# EFM32PG23B310F128IM48 register map
Vendor: Silicon Labs; Series: EFM32; File version: B
Registers are 32-bit, read-write, reset 0x0 unless marked. A register's access mark holds for its fields unless they carry their own. Offsets are from the block's base; [hi:lo] are bit positions; lines under a group give offsets from that group; {n}, {i} and the like mark numbered series; 'fields as' and 'values as' point back to an identical list.

## IADC0_S — IADC0_S Registers
Base 0x49004000
Same registers: IADC0_NS 0x59004000
0x00 IPVERSION ro reset 0x2
  [31:0] IPVERSION — IP version ID
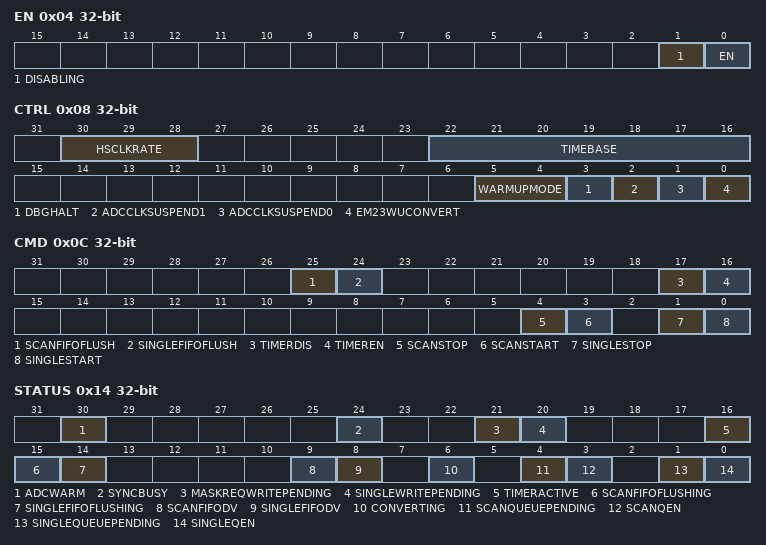
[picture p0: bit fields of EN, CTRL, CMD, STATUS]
0x04 EN — Enable
  [1] DISABLING ro — Disablement busy status
  [0] EN — Enable IADC Module
    0=DISABLE; 1=ENABLE
0x08 CTRL — Control
  [30:28] HSCLKRATE — High Speed Clock Rate
    0=DIV1 (Use CMU_CLK_ADC directly. The source clock must be 40 MHz or less.); 1=DIV2 (Divide CMU_CLK_ADC by 2 before using it. The resulting CLK_SRC_ADC must be 40 MHz or less.); 2=DIV3 (Divide CMU_CLK_ADC by 3 before using it. The resulting CLK_SRC_ADC must be 40 MHz or less.); 3=DIV4 (Divide CMU_CLK_ADC by 4 before using it. The resulting CLK_SRC_ADC must be 40 MHz or less.)
  [22:16] TIMEBASE
  [5:4] WARMUPMODE
    0=NORMAL (Shut down the IADC after conversions have completed.); 1=KEEPINSTANDBY (Switch to standby mode after conversions have completed. The next warmup time will require 1us.); 2=KEEPWARM (Keep IADC fully powered after conversions have completed.)
  [3] DBGHALT — Debug Halt
    0=NORMAL (Continue operation as normal during debug mode); 1=HALT (Complete the current conversion and then halt during debug mode)
  [2] ADCCLKSUSPEND1 — ADC_CLK Suspend - PRS1
    0=PRSWUDIS (Normal mode which does not disable the ADC_CLK.); 1=PRSWUEN (ADCCLKWUEN will gate off ADC_CLK until the trigger is detected provided the internal timer is not selected as the trigger. Once the trigger is detected the ADC_CLK will be started, the band gap will be started, the ADC will be warmed up, and the SCAN Table and the Single entry will be converted. Once the conversions are done, the ADC_CLK will be gated off.)
  [1] ADCCLKSUSPEND0 — ADC_CLK Suspend - PRS0
    values as ADCCLKSUSPEND1
  [0] EM23WUCONVERT — EM23 Wakeup on Conversion
    0=WUDVL (When using suspend mode, conversions performed in EM2 or EM3 should not wake up the DMA until the FIFO's DVL setting is reached. This saves more power for large OSR settings or infrequent sampling.); 1=WUCONVERT (When using suspend mode, conversions performed in EM2 or EM3 will wake up the DMA and keep it awake until the conversions are done, regardless of the DVL setting. This mode burns more power, but it is useful when the conversion rate is faster than the time for the DMA to cycle through wake up and going back to sleep as it converts more than 4 scan table entries. Without using the wake up on conversion mode, the FIFO may overflow while the DMA is going in and out of sleep.)
0x0C CMD wo — Command
  [25] SCANFIFOFLUSH — Flush the Scan FIFO
  [24] SINGLEFIFOFLUSH — Flush the Single FIFO
  [17] TIMERDIS — Timer Disable
  [16] TIMEREN — Timer Enable
  [4] SCANSTOP — Scan Queue Stop
  [3] SCANSTART — Scan Queue Start
  [1] SINGLESTOP — Single Queue Stop
  [0] SINGLESTART — Single Queue Start
0x10 TIMER
  [15:0] TIMER — Timer Period
0x14 STATUS ro
  [30] ADCWARM
  [24] SYNCBUSY
  [21] MASKREQWRITEPENDING
  [20] SINGLEWRITEPENDING
  [16] TIMERACTIVE
  [15] SCANFIFOFLUSHING — The Scan FIFO is flushing
  [14] SINGLEFIFOFLUSHING — The Single FIFO is flushing
  [9] SCANFIFODV — SCANFIFO Data Valid
  [8] SINGLEFIFODV — SINGLEFIFO Data Valid
  [6] CONVERTING
  [4] SCANQUEUEPENDING
  [3] SCANQEN — Scan Queued Enabled
  [1] SINGLEQUEUEPENDING
  [0] SINGLEQEN — Single Queue Enabled
0x18 MASKREQ — Mask Request
  [15:0] MASKREQ — Scan Queue Mask Request
0x1C STMASK ro — Scan Table Mask
  [15:0] STMASK
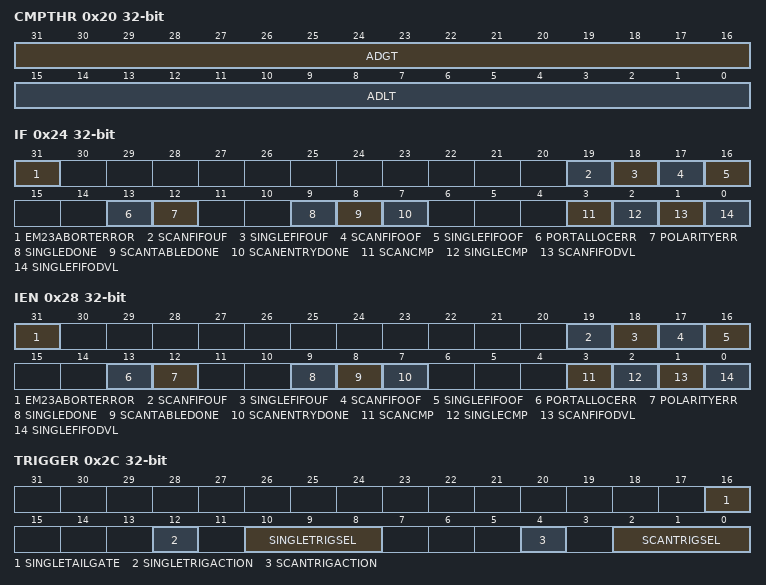
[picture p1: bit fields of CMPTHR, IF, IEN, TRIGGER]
0x20 CMPTHR — Comparator Threshold
  [31:16] ADGT — ADC Greater Than or Equal to Threshold
  [15:0] ADLT — ADC Less Than or Equal to Threshold
0x24 IF — Interrupt Flag
  [31] EM23ABORTERROR
  [19] SCANFIFOUF — Scan FIFO Underflow
  [18] SINGLEFIFOUF — Single FIFO Underflow
  [17] SCANFIFOOF — Scan FIFO Overflow
  [16] SINGLEFIFOOF — Single FIFO Overflow
  [13] PORTALLOCERR — Port Allocation Error
  [12] POLARITYERR — Polarity Error
  [9] SINGLEDONE — Single Conversion Done
  [8] SCANTABLEDONE
  [7] SCANENTRYDONE
  [3] SCANCMP — Scan Result Window Compare
  [2] SINGLECMP — Single Result Window Compare
  [1] SCANFIFODVL — Scan FIFO Data Valid Level
  [0] SINGLEFIFODVL — Single FIFO Data Valid Level
0x28 IEN — Interrupt Enable
  [31] EM23ABORTERROR — EM2/3 Abort Error Enable
  [19] SCANFIFOUF — Scan FIFO Underflow Enable
  [18] SINGLEFIFOUF — Single FIFO Underflow Enable
  [17] SCANFIFOOF — Scan FIFO Overflow Enable
  [16] SINGLEFIFOOF — Single FIFO Overflow Enable
  [13] PORTALLOCERR — Port Allocation Error Enable
  [12] POLARITYERR — Polarity Error Enable
  [9] SINGLEDONE — Single Conversion Done Enable
  [8] SCANTABLEDONE — Scan Table Done Enable
  [7] SCANENTRYDONE — Scan Entry Done Enable
  [3] SCANCMP — Scan Result Window Compare Enable
  [2] SINGLECMP — Single Result Window Compare Enable
  [1] SCANFIFODVL — Scan FIFO Data Valid Level Enable
  [0] SINGLEFIFODVL — Single FIFO Data Valid Level Enable
0x2C TRIGGER
  [16] SINGLETAILGATE — Single Tailgate Enable
    0=TAILGATEOFF (The single queue is ready to start warming up and converting once the trigger had been detected.); 1=TAILGATEON (After the single queue's trigger is detected, it must wait until the end of a scan operation before the Single queue can be converted.)
  [12] SINGLETRIGACTION — Single Trigger Action
    0=ONCE (For TRIGSEL=IMMEDIATE, converts the single queue once and disables queue. For TRIGSEL = TIMER, PRSCLKGRP, PRSPOS, PRSNEG, converts the single queue once per trigger.); 1=CONTINUOUS (Converts the single queue, then checks for a pending scan queue before converting the single queue again continuously. The queues are first come first serve. If both queues are continuous, the IADC alternates between them.)
  [10:8] SINGLETRIGSEL — Single Trigger Select
    0=IMMEDIATE (Immediate triggering. The single queue will be disabled once the conversion is complete, unless TRIGGERACTION is set to continuous.); 1=TIMER (Triggers when the local timer count reaches zero.); 2=PRSCLKGRP (Triggers on PRS1 from a timer module that is using the same clock group as the ADC and has been programmed to use the same clock source as the ADC. The prescale may be different between the ADC and the timer module.); 3=PRSPOS (Triggers on asynchronous PRS1 positive edge. Requires PRS1 to go low for 3 ADC_CLKs before another positive edge can be detected. Generates an additional delay of 1 to 2 ADC_SRC_CLK cycles for synchronization.); 4=PRSNEG (Triggers on asynchronous PRS1 negative edge. Requires PRS1 to go high for 3 ADC_CLKs before another negative edge can be detected. Generates an additional delay of 1 to 2 ADC_SRC_CLK cycles for synchronization. PRSNEG should only be used when the trigger source is from a module that remains powered during EM23. For modules (ie: TIMER) that power down during EM23, PRSPOS should be used for an asynchronous trigger, and PRSCLKGRP should be used for a synchronous trigger.)
  [4] SCANTRIGACTION — Scan Trigger Action
    0=ONCE (For TRIGSEL=IMMEDIATE, goes through the scan table once and disables queue. For TRIGSEL = TIMER, PRSCLKGRP, PRSPOS, PRSNEG, goes through the scan table once per trigger.); 1=CONTINUOUS (Goes through the scan table, converts each entry with a mask bit set, and puts it back into the scan queue to repeat again continuously. The queues are first come first serve. If both queues are triggered, the single queue will get to convert after each scan table completes. The scan queue will get to convert after each single conversion completes.)
  [2:0] SCANTRIGSEL — Scan Trigger Select
    0=IMMEDIATE (Immediate triggering. The scan queue will be disabled once all conversions in the scan table are complete, unless TRIGGERACTION is set to continuous.); 1=TIMER (Triggers when the local timer count reaches zero.); 2=PRSCLKGRP (Triggers on PRS0 from a timer module that is using the same clock group as the ADC and has been programmed to use the same clock source as the ADC. The prescale may be different between the ADC and the timer module.); 3=PRSPOS (Triggers on asynchronous PRS0 positive edge. Requires PRS0 to go low for 3 ADC_CLKs before another positive edge can be detected. Generates an additional delay of 1 to 2 ADC_SRC_CLK cycles for synchronization.); 4=PRSNEG (Triggers on asynchronous PRS0 negative edge. Requires PRS0 to go high for 3 ADC_CLKs before another negative edge can be detected. Generates an additional delay of 1 to 2 ADC_SRC_CLK cycles for synchronization. PRSNEG should only be used when the trigger source is from a module that remains powered during EM23. For modules (ie: TIMER) that power down during EM23, PRSPOS should be used for an asynchronous trigger, and PRSCLKGRP should be used for a synchronous trigger.); 5=LESENSE (Triggers on LESENSE convert request. When using the LESENSE for the SCAN Table, only one entry is converted per LESENSE convert request.)
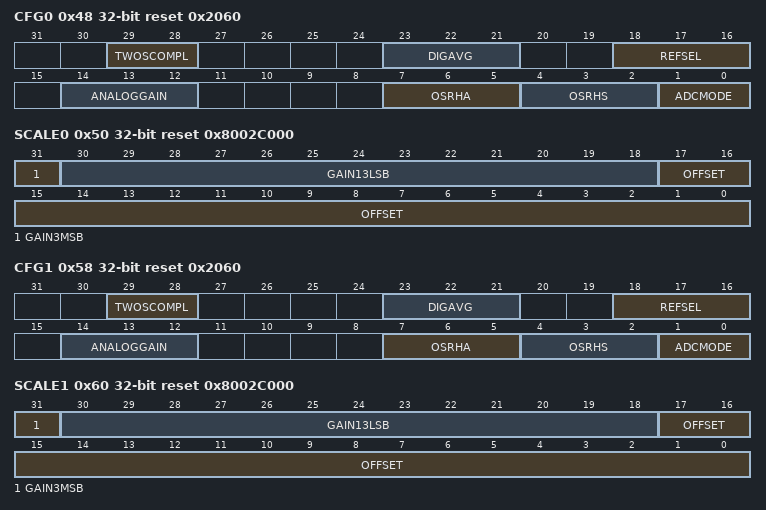
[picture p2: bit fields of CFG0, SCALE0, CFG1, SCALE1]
0x48 CFG0 reset 0x2060 — Configration
  [29:28] TWOSCOMPL — Two's Complement
    0=AUTO (Automatic: Single ended measurements are reported as unipolar and differential measurements are reported as bipolar.); 1=FORCEUNIPOLAR (Force all measurements to result in unipolar output. Negative differential numbers will saturate to 0.); 2=FORCEBIPOLAR (Force all measurements to result in bipolar output. Single ended measurements are half the range, but allow for small negative measurements.)
  [23:21] DIGAVG — Digital Averaging
    0=AVG1 (Collect one output word (no digital averaging).); 1=AVG2 (Collect and average 2 digital output words.); 2=AVG4 (Collect and average 4 digital output words.); 3=AVG8 (Collect and average 8 digital output words.); 4=AVG16 (Collect and average 16 digital output words.)
  [18:16] REFSEL — Reference Select
    0=VBGR (Internal 1.21 V reference.); 1=VREF (External Reference. (Calibrated for 1.25V nominal.)); 2=VREF2P5 (External Reference. Supports 2.5V in high accuracy mode.); 3=VDDX (AVDD (unbuffered)); 4=VDDX0P8BUF (AVDD (buffered) * 0.8)
  [14:12] ANALOGGAIN
    1=ANAGAIN0P5 (Analog gain of 0.5x.); {v}=ANAGAIN{v-1} (Analog gain of {v-1}x.) (v=2..5)
  [7:5] OSRHA — High Accuracy OSR
    0=HIACC16 (High accuracy over sampling of 16x.); 1=HIACC32 (High accuracy over sampling of 32x.); 2=HIACC64 (High accuracy over sampling of 64x.); 3=HIACC92 (High accuracy over sampling of 92x.); 4=HIACC128 (High accuracy over sampling of 128x.); 5=HIACC256 (High accuracy over sampling of 256x.)
  [4:2] OSRHS — High Speed OSR
    0=HISPD2 (High speed over sampling of 2x.); 1=HISPD4 (High speed over sampling of 4x.); 2=HISPD8 (High speed over sampling of 8x.); 3=HISPD16 (High speed over sampling of 16x.); 4=HISPD32 (HIgh speed over sampling of 32x.); 5=HISPD64 (High speed over sampling of 64x.)
  [1:0] ADCMODE
    0=NORMAL (High speed mode with a maximum CLK_ADC of 10 MHz.); 1=HIGHSPEED (Double high speed mode with a maximum CLK_ADC of 20 MHz. Power consumption is boosted to allow faster conversions.); 2=HIGHACCURACY (High accuracy mode with maximum CLK_ADC of 5 MHz.)
0x50 SCALE0 reset 0x8002C000 — Scale
  [31] GAIN3MSB — Gain 3 MSBs
    0=GAIN011 (Upper 3 bits of gain = 011 (0.75x)); 1=GAIN100 (Upper 3 bits of gain = 100 (1.00x))
  [30:18] GAIN13LSB — Gain 13 LSBs
  [17:0] OFFSET
0x54 SCHED0 — Scheduling
  [9:0] PRESCALE
0x58 CFG1 reset 0x2060 — Configration
  fields as CFG0
0x60 SCALE1 reset 0x8002C000 — Scale
  fields as SCALE0
0x64 SCHED1 — Scheduling
  [9:0] PRESCALE
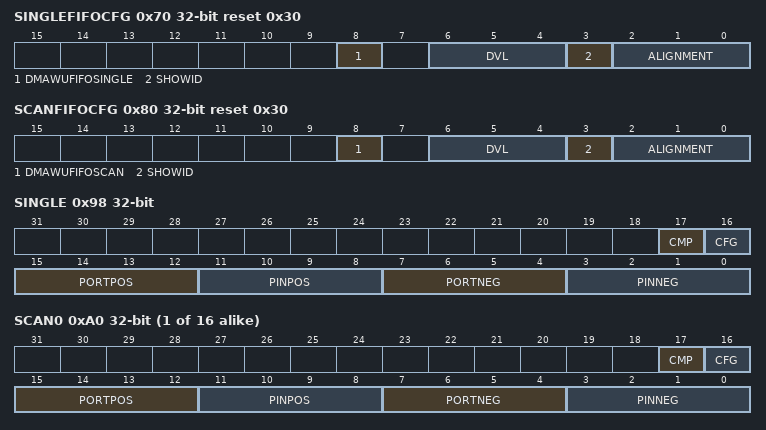
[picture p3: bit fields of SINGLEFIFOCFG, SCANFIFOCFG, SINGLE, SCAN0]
0x70 SINGLEFIFOCFG reset 0x30 — Single FIFO Configuration
  [8] DMAWUFIFOSINGLE — Single FIFO DMA wakeup.
    0=DISABLED (While in EM2 or EM3, the DMA controller will not be requested.); 1=ENABLED (While in EM2 or EM3, the DMA controller will be requested when the single FIFO reaches its Data Valid Level. [DVL must be set to 0 (VALID1).])
  [6:4] DVL — Data Valid Level
    0=VALID1 (When 1 entry in the single FIFO is valid, set the SINGLEFIFODVL interrupt and request DMA.); {v}=VALID{v+1} (When {v+1} entries in the single FIFO are valid, set the SINGLEFIFODVL interrupt and request DMA.) (v=1..7)
  [3] SHOWID
  [2:0] ALIGNMENT
    0=RIGHT12 (ID[7:0], SIGN_EXT, DATA[11:0]); 1=RIGHT16 (ID[7:0], SIGN_EXT, DATA[15:0]); 2=RIGHT20 (ID[7:0], SIGN_EXT, DATA[19:0]); 3=LEFT12 (DATA[11:0], 000000000000, ID[7:0]); 4=LEFT16 (DATA[15:0], 00000000, ID[7:0]); 5=LEFT20 (DATA[19:0], 0000, ID[7:0])
0x74 SINGLEFIFODATA ro — Read the oldest valid data from the single FIFO and pop the FIFO
  [31:0] DATA — Single FIFO Read Data
0x78 SINGLEFIFOSTAT ro — Single FIFO status
  [3:0] FIFOREADCNT — FIFO Read Count
0x7C SINGLEDATA ro — latest single queue conversion data
  [31:0] DATA
0x80 SCANFIFOCFG reset 0x30 — SCAN FIFO configuration
  [8] DMAWUFIFOSCAN — Scan FIFO DMA Wakeup
    0=DISABLED (While in EM2 or EM3, the DMA controller will not be requested.); 1=ENABLED (While in EM2 or EM3, the DMA controller will be requested when the scan FIFO reaches its Data Valid Level. [DVL must be set to 0 (VALID1).])
  [6:4] DVL — Data Valid Level
    0=VALID1 (When 1 entry in the scan FIFO is valid, set the SCANFIFODVL interrupt and request DMA.); {v}=VALID{v+1} (When {v+1} entries in the scan FIFO are valid, set the SCANFIFODVL interrupt and request DMA.) (v=1..7)
  [3] SHOWID
  [2:0] ALIGNMENT
    values as SINGLEFIFOCFG.ALIGNMENT
0x84 SCANFIFODATA ro — Read the oldest valid data from the scan FIFO and pop the FIFO
  [31:0] DATA
0x88 SCANFIFOSTAT ro — Scan FIFO status
  [3:0] FIFOREADCNT — FIFO Read Count
0x8C SCANDATA ro — Most recent data data from scan queue conversion
  [31:0] DATA
0x98 SINGLE
  [17] CMP — Comparison Enable
  [16] CFG — Configuration Group Select
    0=CONFIG0 (Use configuration group 0); 1=CONFIG1 (Use configuration group 1)
  [15:12] PORTPOS — Positive Port Select
    0=GND (Ground); 1=SUPPLY (Supply Pin - Select specific supply using PINPOS); 2=DAC0 (Direct connection to DAC0_CH0); 4=PADANA0 (Direct connection to AIN0 input pin); 8=PORTA (Port A - Select pin number using PINPOS); 9=PORTB (Port B - Select pin number using PINPOS); 10=PORTC (Port C - Select pin number using PINPOS); 11=PORTD (Port D - Select pin number using PINPOS)
  [11:8] PINPOS — Positive Pin Select
  [7:4] PORTNEG — Negative Port Select
    0=GND (Ground (single-ended)); 2=DAC1 (Direct connection to DAC0_CH1); 4=PADANA1 (Direct connection to AIN1 input pin); 8=PORTA (Port A - Select pin number using PINNEG); 9=PORTB (Port B - Select pin number using PINNEG); 10=PORTC (Port C - Select pin number using PINNEG); 11=PORTD (Port D - Select pin number using PINNEG)
  [3:0] PINNEG — Negative Pin Select
{0xA0+4i} SCAN{i} (i=0..15)
  fields as SINGLE
